VERSION ""

NS_ :

BS_:

BU_: suprevisor Hmi

BO_ 2147523649 FC_DCDC_STATUS: 2 Hmi
 SG_ FC_DCDC_RUNNING : 7|1@0+ (1,0) [0|0] ""  Hmi
 SG_ FC_DCDC_FAILURE : 6|1@0+ (1,0) [0|0] ""  Hmi

BO_ 2147523651 DCDC_VOLTAGE: 2 Hmi
 SG_ DCDC_VOLTAGE : 7|16@0+ (0.1,0) [0|0] "V"  Hmi

BO_ 2147523652 FC_DCDC_CURRENT: 2 Hmi
 SG_ FC_DCDC_CURRENT : 7|16@0+ (0.01,0) [0|0] "A"  Hmi

BO_ 2147523653 FC_DCDC_POWER: 2 Hmi
 SG_ FC_DCDC_POWER : 7|16@0+ (0.01,0) [0|0] "kW"  Hmi

BO_ 2147523654 FC_DCDC_POWER_LIMITATION: 2 Hmi
 SG_ FC_DCDC_POWER_LIMITATION : 7|16@0+ (0.01,0) [0|0] "kW"  Hmi

BO_ 2147523655 DCDC_COMMAND: 2 Hmi
 SG_ DCDC_RESET2 : 7|1@0+ (1,0) [0|0] ""  Hmi

BO_ 2147513649 FCSTACK_STATUS: 2 Hmi
 SG_ FCSTACK_STATUS : 7|8@0+ (1,0) [0|0] ""  Hmi

BO_ 2147513650 DCDC_STATUS: 2 Hmi
 SG_ DCDC_STATUS : 7|8@0+ (1,0) [0|0] ""  Hmi

BO_ 2147513651 DCDC_PWR_UNIT_TEMPERATURE: 2 Hmi
 SG_ DCDC_PWR_UNIT_TEMPERATURE : 7|16@0+ (0.1,0) [0|0] "°C"  Hmi

BO_ 2147513652 DCDC_MAX_AVAILABLE_CURRENT: 2 Hmi
 SG_ DCDC_MAX_AVAILABLE_CURRENT : 7|16@0+ (0.1,0) [0|0] "A"  Hmi

BO_ 2147513653 DCDC_MAX_AVAILABLE_FC_CURRENT: 2 Hmi
 SG_ DCDC_MAX_AVAILABLE_FC_CURRENT : 7|16@0+ (0.1,0) [0|0] "A"  Hmi

BO_ 2147513654 DCDC_MAX_AVAILABLE_POWER: 2 Hmi
 SG_ DCDC_MAX_AVAILABLE_POWER : 7|16@0+ (0.01,0) [0|0] "kW"  Hmi

BO_ 2147513655 FCSTACK_VOLTAGE: 2 Hmi
 SG_ FCSTACK_VOLTAGE : 7|16@0+ (0.1,0) [0|0] "V"  Hmi

BO_ 2147513656 FCSTACK_CURRENT: 2 Hmi
 SG_ FCSTACK_CURRENT : 7|16@0+ (0.1,0) [0|0] "A"  Hmi

BO_ 2147513657 DC_BUS_VOLTAGE: 2 Hmi
 SG_ DC_BUS_VOLTAGE : 7|16@0+ (0.1,0) [0|0] "V"  Hmi

BO_ 2147513658 DC_BUS_CURRENT: 2 Hmi
 SG_ DC_BUS_CURRENT : 7|16@0+ (0.01,0) [0|0] "A"  Hmi

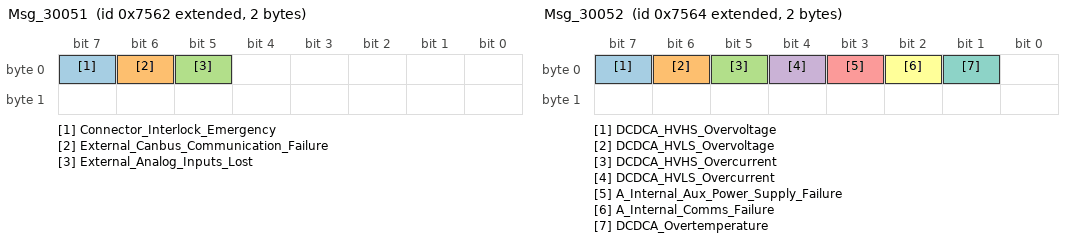
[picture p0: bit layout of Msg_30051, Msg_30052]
BO_ 2147513698 Msg_30051: 2 Hmi
 SG_ Connector_Interlock_Emergency : 7|1@0+ (1,0) [0|0] ""  Hmi
 SG_ External_Canbus_Communication_Failure : 6|1@0+ (1,0) [0|0] ""  Hmi
 SG_ External_Analog_Inputs_Lost : 5|1@0+ (1,0) [0|0] ""  Hmi

BO_ 2147513700 Msg_30052: 2 Hmi
 SG_ DCDCA_HVHS_Overvoltage : 7|1@0+ (1,0) [0|0] ""  Hmi
 SG_ DCDCA_HVLS_Overvoltage : 6|1@0+ (1,0) [0|0] ""  Hmi
 SG_ DCDCA_HVHS_Overcurrent : 5|1@0+ (1,0) [0|0] ""  Hmi
 SG_ DCDCA_HVLS_Overcurrent : 4|1@0+ (1,0) [0|0] ""  Hmi
 SG_ A_Internal_Aux_Power_Supply_Failure : 3|1@0+ (1,0) [0|0] ""  Hmi
 SG_ A_Internal_Comms_Failure : 2|1@0+ (1,0) [0|0] ""  Hmi
 SG_ DCDCA_Overtemperature : 1|1@0+ (1,0) [0|0] ""  Hmi

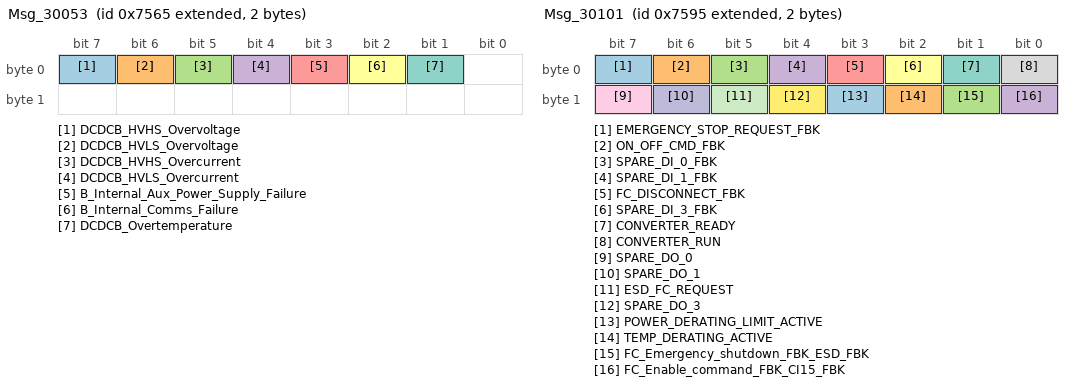
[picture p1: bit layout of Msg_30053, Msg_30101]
BO_ 2147513701 Msg_30053: 2 Hmi
 SG_ DCDCB_HVHS_Overvoltage : 7|1@0+ (1,0) [0|0] ""  Hmi
 SG_ DCDCB_HVLS_Overvoltage : 6|1@0+ (1,0) [0|0] ""  Hmi
 SG_ DCDCB_HVHS_Overcurrent : 5|1@0+ (1,0) [0|0] ""  Hmi
 SG_ DCDCB_HVLS_Overcurrent : 4|1@0+ (1,0) [0|0] ""  Hmi
 SG_ B_Internal_Aux_Power_Supply_Failure : 3|1@0+ (1,0) [0|0] ""  Hmi
 SG_ B_Internal_Comms_Failure : 2|1@0+ (1,0) [0|0] ""  Hmi
 SG_ DCDCB_Overtemperature : 1|1@0+ (1,0) [0|0] ""  Hmi

BO_ 2147513709 DCDC_WARNING_WORD_1: 2 Hmi
 SG_ DCDC_WARNING_WORD_1 : 7|16@0+ (0.01,0) [0|0] "A"  Hmi

BO_ 2147513710 DCDC_WARNING_WORD_2: 2 Hmi
 SG_ DCDC_WARNING_WORD_2 : 7|16@0+ (0.01,0) [0|0] "A"  Hmi

BO_ 2147513711 DCDC_WARNING_WORD_3: 2 Hmi
 SG_ DCDC_WARNING_WORD_3 : 7|16@0+ (0.01,0) [0|0] "A"  Hmi

BO_ 2147513749 Msg_30101: 2 Hmi
 SG_ EMERGENCY_STOP_REQUEST_FBK : 7|1@0+ (1,0) [0|0] ""  Hmi
 SG_ ON_OFF_CMD_FBK : 6|1@0+ (1,0) [0|0] ""  Hmi
 SG_ SPARE_DI_0_FBK : 5|1@0+ (1,0) [0|0] ""  Hmi
 SG_ SPARE_DI_1_FBK : 4|1@0+ (1,0) [0|0] ""  Hmi
 SG_ FC_DISCONNECT_FBK : 3|1@0+ (1,0) [0|0] ""  Hmi
 SG_ SPARE_DI_3_FBK : 2|1@0+ (1,0) [0|0] ""  Hmi
 SG_ CONVERTER_READY : 1|1@0+ (1,0) [0|0] ""  Hmi
 SG_ CONVERTER_RUN : 0|1@0+ (1,0) [0|0] ""  Hmi
 SG_ SPARE_DO_0 : 15|1@0+ (1,0) [0|0] ""  Hmi
 SG_ SPARE_DO_1 : 14|1@0+ (1,0) [0|0] ""  Hmi
 SG_ ESD_FC_REQUEST : 13|1@0+ (1,0) [0|0] ""  Hmi
 SG_ SPARE_DO_3 : 12|1@0+ (1,0) [0|0] ""  Hmi
 SG_ POWER_DERATING_LIMIT_ACTIVE : 11|1@0+ (1,0) [0|0] ""  Hmi
 SG_ TEMP_DERATING_ACTIVE : 10|1@0+ (1,0) [0|0] ""  Hmi
 SG_ FC_Emergency_shutdown_FBK_ESD_FBK : 9|1@0+ (1,0) [0|0] ""  Hmi
 SG_ FC_Enable_command_FBK_CI15_FBK : 8|1@0+ (1,0) [0|0] ""  Hmi

BO_ 2147523849 PowerCurrentMode: 2 Hmi
 SG_ PowerCurrentMode : 7|8@0+ (1,0) [0|0] ""  Hmi

BO_ 2147523850 PowerCurrentReference: 2 Hmi
 SG_ PowerCurrentReference : 7|8@0+ (1,0) [0|0] ""  Hmi

BO_ 2147523851 PowerCurrentMinHandling: 2 Hmi
 SG_ PowerCurrentMinHandling : 7|8@0+ (1,0) [0|0] ""  Hmi

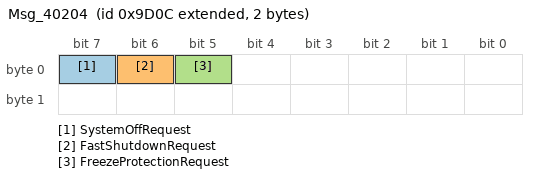
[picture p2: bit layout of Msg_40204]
BO_ 2147523852 Msg_40204: 2 Hmi
 SG_ SystemOffRequest : 7|1@0+ (1,0) [0|0] ""  Hmi
 SG_ FastShutdownRequest : 6|1@0+ (1,0) [0|0] ""  Hmi
 SG_ FreezeProtectionRequest : 5|1@0+ (1,0) [0|0] ""  Hmi

BO_ 2147513849 Msg_30201: 2 Hmi
 SG_ Mute_H2_Sens_Exhaust2 : 7|1@0+ (1,0) [0|0] ""  Hmi
 SG_ Status_Freeze_Protection : 6|1@0+ (1,0) [0|0] ""  Hmi

BO_ 2147513850 Pos_Mix_Valve: 2 Hmi
 SG_ Pos_Mix_Valve2 : 7|8@0+ (1,0) [0|0] "%"  Hmi

BO_ 2147513851 Tcm_Hs_Pri_Out: 2 Hmi
 SG_ Tcm_Hs_Pri_Out2 : 7|16@0+ (0.1,0) [0|0] "°C"  Hmi

BO_ 2147513852 Tcm_Hs_Sec_In_Sp: 2 Hmi
 SG_ Tcm_Hs_Sec_In_Sp2 : 7|16@0+ (0.1,0) [0|0] "°C"  Hmi

BO_ 2147513853 FC_POWER_ACT: 2 Hmi
 SG_ FC_POWER_ACT : 7|16@0+ (10,0) [0|0] "W"  Hmi

BO_ 2147513854 FC_POWER_PERIPHERAL: 2 Hmi
 SG_ FC_POWER_PERIPHERAL : 7|16@0+ (10,0) [0|0] "W"  Hmi

BO_ 2147513855 FC_POWER_OPT: 2 Hmi
 SG_ FC_POWER_OPT : 7|16@0+ (10,0) [0|0] "W"  Hmi

BO_ 2147513856 FC_POWER_MAX: 2 Hmi
 SG_ FC_POWER_MAX : 7|16@0+ (10,0) [0|0] "W"  Hmi

BO_ 2147513857 FC_POWER_MAX_STATE: 2 Hmi
 SG_ FC_POWER_MAX_STATE : 7|16@0+ (10,0) [0|0] "W"  Hmi

BO_ 2147513858 FC_POWER_MIN: 2 Hmi
 SG_ FC_POWER_MIN : 7|16@0+ (10,0) [0|0] "W"  Hmi

BO_ 2147513859 EstimatedTimeToPower: 2 Hmi
 SG_ EstimatedTimeToPower : 7|16@0+ (1,0) [0|0] "sec"  Hmi

BO_ 2147513860 EstimatedTimeForShutdown: 2 Hmi
 SG_ EstimatedTimeForShutdown : 7|16@0+ (1,0) [0|0] "sec"  Hmi

BO_ 2147513861 FC_POWER_SP: 2 Hmi
 SG_ FC_POWER_SP : 7|16@0+ (10,0) [0|0] "W"  Hmi

BO_ 2147513899 FC_EVENT_CODE: 4 Hmi
 SG_ FC_EVENT_CODE1 : 7|16@0+ (1,0) [0|0] ""  Hmi
 SG_ FC_EVENT_CODE2 : 23|16@0+ (1,0) [0|0] "" Vector__XXX

BO_ 2147513901 FC_EXTENDED_INFO: 4 Hmi
 SG_ FC_EXTENDED_INFO2 : 23|16@0+ (1,0) [0|0] ""  Hmi
 SG_ FC_EXTENDED_INFO1 : 7|16@0+ (1,0) [0|0] "" Vector__XXX

BA_DEF_  "BusType" STRING ;
BA_DEF_ BU_  "StationAddress" INT 1 255;
BA_DEF_DEF_  "BusType" "";
BA_DEF_DEF_  "StationAddress" 1;
BA_ "BusType" "MODBUS";
